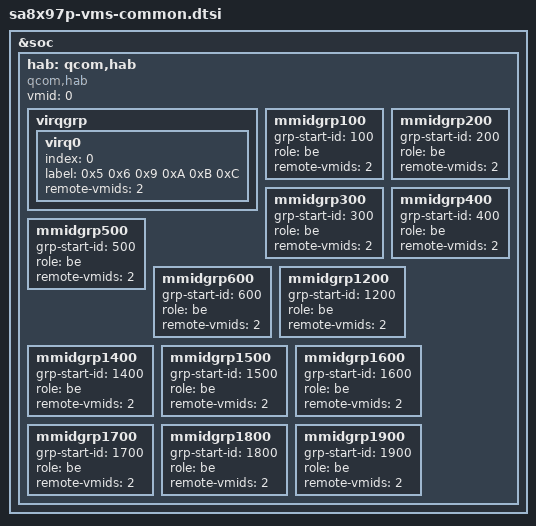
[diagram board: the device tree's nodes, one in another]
// SPDX-License-Identifier: BSD-3-Clause
/*
* Copyright (c) Qualcomm Technologies, Inc. and/or its subsidiaries.
*/

#ifndef _SA8X97P_VMS_COMMON_DTSI_
#define _SA8X97P_VMS_COMMON_DTSI_

#include "oot-dt-bindings/qcom-shmem-sa8797p.h"

&soc {
	hab: qcom,hab {
		compatible = "qcom,hab";
		vmid = <0>;

		virqgrp: virqgrp {
			virq0: virq0 {
				index = <0>;
				label = <0x5 0x6 0x9 0xA 0xB 0xC>;
				remote-vmids = <2>;
			};
		};

		mmidgrp100: mmidgrp100 {
			grp-start-id = <100>;
			role = "be";
			remote-vmids = <2>;
		};

		mmidgrp200: mmidgrp200 {
			grp-start-id = <200>;
			role = "be";
			remote-vmids = <2>;
		};

		mmidgrp300: mmidgrp300 {
			grp-start-id = <300>;
			role = "be";
			remote-vmids = <2>;
		};

		mmidgrp400: mmidgrp400 {
			grp-start-id = <400>;
			role = "be";
			remote-vmids = <2>;
		};

		mmidgrp500: mmidgrp500 {
			grp-start-id = <500>;
			role = "be";
			remote-vmids = <2>;
		};

		mmidgrp600: mmidgrp600 {
			grp-start-id = <600>;
			role = "be";
			remote-vmids = <2>;
		};

		mmidgrp1200: mmidgrp1200 {
			grp-start-id = <1200>;
			role = "be";
			remote-vmids = <2>;
		};

		mmidgrp1400: mmidgrp1400 {
			grp-start-id = <1400>;
			role = "be";
			remote-vmids = <2>;
		};

		mmidgrp1500: mmidgrp1500 {
			grp-start-id = <1500>;
			role = "be";
			remote-vmids = <2>;
		};

		mmidgrp1600: mmidgrp1600 {
			grp-start-id = <1600>;
			role = "be";
			remote-vmids = <2>;
		};

		mmidgrp1700: mmidgrp1700 {
			grp-start-id = <1700>;
			role = "be";
			remote-vmids = <2>;
		};

		mmidgrp1800: mmidgrp1800 {
			grp-start-id = <1800>;
			role = "be";
			remote-vmids = <2>;
		};

		mmidgrp1900: mmidgrp1900 {
			grp-start-id = <1900>;
			role = "be";
			remote-vmids = <2>;
		};
	};
};

#endif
